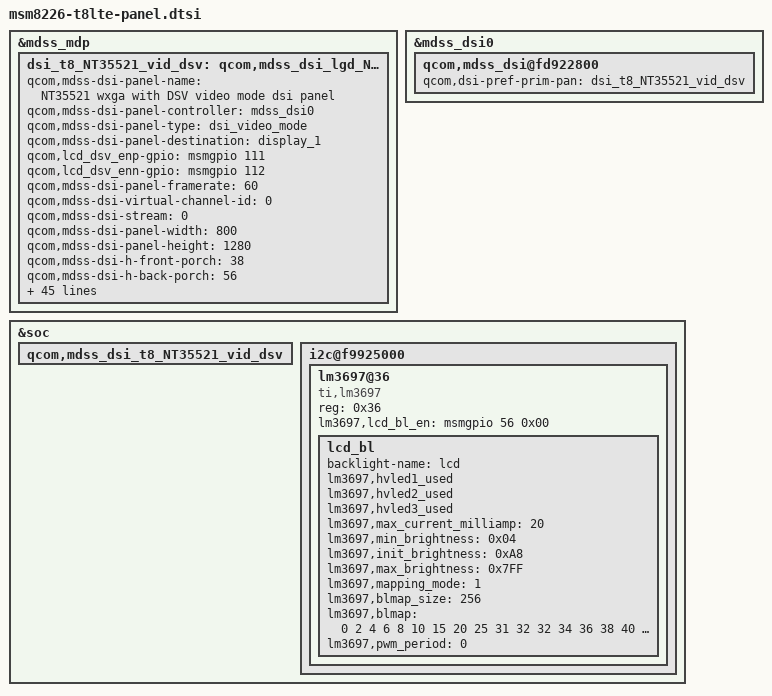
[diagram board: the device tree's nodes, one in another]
/* Copyright (c) 2013, The Linux Foundation. All rights reserved.
 *
 * This program is free software; you can redistribute it and/or modify
 * it under the terms of the GNU General Public License version 2 and
 * only version 2 as published by the Free Software Foundation.
 *
 * This program is distributed in the hope that it will be useful,
 * but WITHOUT ANY WARRANTY; without even the implied warranty of
 * MERCHANTABILITY or FITNESS FOR A PARTICULAR PURPOSE.  See the
 * GNU General Public License for more details.
 */

/*---------------------------------------------------------------------------
 * This file is autogenerated file using gcdb parser. Please do not edit it.
 * Update input XML file to add a new entry or update variable in this file
 * VERSION = "1.0"
 *---------------------------------------------------------------------------*/
&mdss_mdp {
	dsi_t8_NT35521_vid_dsv: qcom,mdss_dsi_lgd_NT35521_t8_wxga_video {
		qcom,mdss-dsi-panel-name = "NT35521 wxga with DSV video mode dsi panel";
		qcom,mdss-dsi-panel-controller = <&mdss_dsi0>;
		qcom,mdss-dsi-panel-type = "dsi_video_mode";
		qcom,mdss-dsi-panel-destination = "display_1";
		qcom,lcd_dsv_enp-gpio = <&msmgpio 111 0>;
		qcom,lcd_dsv_enn-gpio = <&msmgpio 112 0>;
		qcom,mdss-dsi-panel-framerate = <60>;
		qcom,mdss-dsi-virtual-channel-id = <0>;
		qcom,mdss-dsi-stream = <0>;
		qcom,mdss-dsi-panel-width = <800>;
		qcom,mdss-dsi-panel-height = <1280>;
		qcom,mdss-dsi-h-front-porch = <38>;
		qcom,mdss-dsi-h-back-porch = <56>;
		qcom,mdss-dsi-h-pulse-width = <4>;
		qcom,mdss-dsi-h-sync-skew = <0>;
		qcom,mdss-dsi-v-front-porch = <24>;
		qcom,mdss-dsi-v-back-porch = <32>;
		qcom,mdss-dsi-v-pulse-width = <4>;
		qcom,mdss-dsi-h-left-border = <0>;
		qcom,mdss-dsi-h-right-border = <0>;
		qcom,mdss-dsi-v-top-border = <0>;
		qcom,mdss-dsi-v-bottom-border = <0>;
		qcom,mdss-pan-physical-width-dimension = < 94 >;
		qcom,mdss-pan-physical-height-dimension = < 150 >;
		qcom,mdss-dsi-bpp = <24>;
		qcom,mdss-dsi-color-order = "rgb_swap_rgb";
		qcom,mdss-dsi-underflow-color = <0x00>;
		qcom,mdss-dsi-border-color = <0>;
		qcom,mdss-dsi-lp11-init =<1>;
		qcom,mdss-dsi-on-command = [
		39 01 00 00 00 00 05 FF AA 55 A5 80
		15 01 00 00 00 00 02 6F 02
		15 01 00 00 00 00 02 F7 47
		15 01 00 00 00 00 02 6F 17
		15 01 00 00 00 00 02 F4 60
		39 01 00 00 00 00 06 F0 55 AA 52 08 00
		39 01 00 00 00 00 03 B1 28 01
		15 01 00 00 00 00 02 B5 C8
		15 01 00 00 00 00 02 B6 05
		39 01 00 00 00 00 05 B8 01 02 0C 02
		39 01 00 00 00 00 03 BB 33 33
		39 01 00 00 00 00 03 BC 05 05
		39 01 00 00 00 00 06 BD 02 67 20 20 00
		15 01 00 00 00 00 02 D0 00
		39 01 00 00 00 00 03 D9 00 01
		15 01 00 00 00 00 02 C8 83
		39 01 00 00 00 00 11 CC 40 36 87 00 00 00 00 00 00 00 00 00 40 08 A5 05
		39 01 00 00 00 00 11 D1 00 06 0A 0E 12 16 22 28 22 20 16 14 12 0E 08 00
		39 01 00 00 00 00 0D D7 26 28 25 23 23 00 00 00 00 00 00 00
		39 01 00 00 00 00 0E D8 00 00 00 00 00 00 00 00 00 00 23 25 00
		39 01 00 00 00 00 06 F0 55 AA 52 08 01
		39 01 00 00 00 00 03 B3 19 19
		39 01 00 00 00 00 03 B4 1E 1E
		39 01 00 00 00 00 03 B9 24 24
		39 01 00 00 00 00 03 BA 36 36
		39 01 00 00 00 00 03 BC 40 10
		39 01 00 00 00 00 03 BD 40 10
		15 01 00 00 00 00 02 C1 01
		15 01 00 00 00 00 02 CA 80
		39 01 00 00 00 00 03 CB 90 F4
		39 01 00 00 00 00 04 CD 15 03 03
		39 01 00 00 00 00 04 CF 00 50 50
		39 01 00 00 00 00 03 D0 50 50
		39 01 00 00 00 00 03 D1 50 50
		15 01 00 00 00 00 02 D2 39
		15 01 00 00 00 00 02 D3 39
		39 01 00 00 00 00 06 F0 55 AA 52 08 02
		15 01 00 00 00 00 02 EE 02
		39 01 00 00 00 00 11 B0 00 44 00 55 00 6A 00 88 00 97 00 BB 00 D2 00 FE
		39 01 00 00 00 00 11 B1 01 23 01 58 01 8A 01 D2 02 11 02 13 02 49 02 87
		39 01 00 00 00 00 11 B2 02 AF 02 E5 03 0B 03 4E 03 6C 03 8E 03 A5 03 C0
		39 01 00 00 00 00 05 B3 03 E8 03 FF
		39 01 00 00 00 00 11 BC 00 0A 00 1C 00 32 00 52 00 62 00 88 00 A1 00 CE
		39 01 00 00 00 00 11 BD 00 F4 01 2F 01 63 01 B0 01 F3 01 F5 02 2E 02 70
		39 01 00 00 00 00 11 BE 02 9A 02 D3 02 FC 03 42 03 63 03 86 03 9E 03 BB
		39 01 00 00 00 00 05 BF 03 E6 03 FF
		39 01 00 00 00 00 06 F0 55 AA 52 08 03
		39 01 00 00 00 00 03 B0 22 00
		39 01 00 00 00 00 03 B1 22 00
		39 01 00 00 00 00 06 B2 05 00 B0 00 00
		39 01 00 00 00 00 06 B3 05 00 B0 00 00
		39 01 00 00 00 00 06 B4 05 00 B0 00 00
		39 01 00 00 00 00 06 B5 05 00 B0 00 00
		39 01 00 00 00 00 06 BA 53 00 B0 00 00
		39 01 00 00 00 00 06 BB 53 00 B0 00 00
		39 01 00 00 00 00 06 BC 53 00 B0 00 00
		39 01 00 00 00 00 06 BD 53 00 B0 00 00
		39 01 00 00 00 00 05 C0 00 60 00 00
		39 01 00 00 00 00 05 C1 00 00 60 00
		39 01 00 00 00 00 05 C2 00 00 34 00
		39 01 00 00 00 00 05 C3 00 00 34 00
		15 01 00 00 00 00 02 C4 60
		15 01 00 00 00 00 02 C5 C0
		15 01 00 00 00 00 02 C6 00
		15 01 00 00 00 00 02 C7 00
		39 01 00 00 00 00 06 F0 55 AA 52 08 05
		39 01 00 00 00 00 03 B0 17 06
		39 01 00 00 00 00 03 B1 17 06
		39 01 00 00 00 00 03 B2 17 06
		39 01 00 00 00 00 03 B3 17 06
		39 01 00 00 00 00 03 B4 17 06
		39 01 00 00 00 00 03 B5 17 06
		39 01 00 00 00 00 03 B6 17 06
		39 01 00 00 00 00 03 B7 17 06
		15 01 00 00 00 00 02 B8 00
		39 01 00 00 00 00 03 B9 00 03
		39 01 00 00 00 00 03 BA 00 00
		39 01 00 00 00 00 03 BB 02 03
		39 01 00 00 00 00 03 BC 02 03
		39 01 00 00 00 00 06 BD 03 03 00 03 03
		15 01 00 00 00 00 02 C0 0B
		15 01 00 00 00 00 02 C1 09
		15 01 00 00 00 00 02 C2 A6
		15 01 00 00 00 00 02 C3 05
		15 01 00 00 00 00 02 C4 00
		15 01 00 00 00 00 02 C5 02
		15 01 00 00 00 00 02 C6 22
		15 01 00 00 00 00 02 C7 03
		39 01 00 00 00 00 03 C8 07 20
		39 01 00 00 00 00 03 C9 03 20
		39 01 00 00 00 00 03 CA 01 60
		39 01 00 00 00 00 03 CB 01 60
		39 01 00 00 00 00 04 CC 00 00 78
		39 01 00 00 00 00 04 CD 00 00 78
		39 01 00 00 00 00 04 CE 00 00 02
		39 01 00 00 00 00 04 CF 00 00 02
		39 01 00 00 00 00 06 D1 00 05 01 07 10
		39 01 00 00 00 00 06 D2 10 05 05 03 10
		39 01 00 00 00 00 06 D3 20 00 43 07 10
		39 01 00 00 00 00 06 D4 30 00 43 07 10
		39 01 00 00 00 00 08 D0 00 00 00 00 00 00 00
		39 01 00 00 00 00 0C D5 00 00 00 00 00 00 00 00 00 00 00
		39 01 00 00 00 00 0C D6 00 00 00 00 00 00 00 00 00 00 00
		39 01 00 00 00 00 0C D7 00 00 00 00 00 00 00 00 00 00 00
		39 01 00 00 00 00 06 D8 00 00 00 00 00
		15 01 00 00 00 00 02 E5 06
		15 01 00 00 00 00 02 E6 06
		15 01 00 00 00 00 02 E7 00
		15 01 00 00 00 00 02 E8 06
		15 01 00 00 00 00 02 E9 06
		15 01 00 00 00 00 02 EA 06
		15 01 00 00 00 00 02 EB 00
		15 01 00 00 00 00 02 EC 00
		15 01 00 00 00 00 02 ED 30
		39 01 00 00 00 00 06 F0 55 AA 52 08 06
		39 01 00 00 00 00 03 B0 34 34
		39 01 00 00 00 00 03 B1 34 34
		39 01 00 00 00 00 03 B2 2D 2E
		39 01 00 00 00 00 03 B3 34 34
		39 01 00 00 00 00 03 B4 29 2A
		39 01 00 00 00 00 03 B5 13 11
		39 01 00 00 00 00 03 B6 19 17
		39 01 00 00 00 00 03 B7 01 03
		39 01 00 00 00 00 03 B8 34 31
		39 01 00 00 00 00 03 B9 31 31
		39 01 00 00 00 00 03 BA 31 31
		39 01 00 00 00 00 03 BB 31 34
		39 01 00 00 00 00 03 BC 02 00
		39 01 00 00 00 00 03 BD 16 18
		39 01 00 00 00 00 03 BE 10 12
		39 01 00 00 00 00 03 BF 2A 29
		39 01 00 00 00 00 03 C0 34 34
		39 01 00 00 00 00 03 C1 2E 2D
		39 01 00 00 00 00 03 C2 34 34
		39 01 00 00 00 00 03 C3 34 34
		39 01 00 00 00 00 06 D8 00 00 00 00 00
		39 01 00 00 00 00 06 D9 00 00 00 00 00
		39 01 00 00 00 00 05 FF AA 55 A5 00
		39 01 00 00 00 00 06 F0 55 AA 52 00 00
		05 01 00 00 78 00 02 11 00
		15 01 00 00 00 00 02 51 FF
		15 01 00 00 00 00 02 53 24
		15 01 00 00 00 00 02 55 80
		05 01 00 00 00 00 02 29 00];
		qcom,mdss-dsi-off-command = [
		05 01 00 00 32 00 02 28 00
		05 01 00 00 78 00 02 10 00
		];
		qcom,mdss-dsi-on-command-state = "dsi_lp_mode";
		qcom,mdss-dsi-off-command-state = "dsi_hs_mode";
		qcom,mdss-dsi-h-sync-pulse = <0>;
		qcom,mdss-dsi-traffic-mode = "non_burst_sync_event";
		qcom,mdss-dsi-lane-map = "lane_map_0123";
		qcom,mdss-dsi-bllp-eof-power-mode;
		qcom,mdss-dsi-bllp-power-mode;
		qcom,mdss-dsi-lane-0-state;
		qcom,mdss-dsi-lane-1-state;
		qcom,mdss-dsi-lane-2-state;
		qcom,mdss-dsi-lane-3-state;
		qcom,mdss-dsi-panel-timings = [7A 1A 12 00 40 4C 12 20 14 03 04 00];
		qcom,mdss-dsi-t-clk-post = <0x04>;
		qcom,mdss-dsi-t-clk-pre = <0x1A>;
		qcom,mdss-dsi-bl-min-level = <1>;
		qcom,mdss-dsi-bl-max-level = <255>;
		qcom,mdss-dsi-dma-trigger = "trigger_sw";
		qcom,mdss-dsi-mdp-trigger = "none";
		qcom,mdss-dsi-bl-pmic-control-type = "bl_ctrl_wled";
		qcom,mdss-dsi-reset-sequence = <1 1>, <0 1>, <1 150>;
	};
};

&mdss_dsi0 {
	qcom,mdss_dsi@fd922800 {
		qcom,dsi-pref-prim-pan = <&dsi_t8_NT35521_vid_dsv>;
	};
};

&dsi_t8_NT35521_vid_dsv {
	qcom,cont-splash-enabled;
	qcom,platform-enable-gpio = <0>;
	status = "ok";
};

&soc {
	qcom,mdss_dsi_t8_NT35521_vid_dsv {
		status = "ok";
	};

    i2c@f9925000 { /* BLSP1 QUP3 */
	lm3697@36 {
		compatible = "ti,lm3697";
		status = "ok";
		reg = <0x36>;
		lm3697,lcd_bl_en = <&msmgpio 56 0x00>;
		lcd_bl {
			backlight-name = "lcd";
			lm3697,hvled1_used;
			lm3697,hvled2_used;
			lm3697,hvled3_used;
			lm3697,max_current_milliamp = <20>;
			lm3697,min_brightness = <0x04>;
			lm3697,init_brightness = <0xA8>;
			lm3697,max_brightness = <0x7FF>;
			/* mapping_mode, 0: exp, 1: linear */
			lm3697,mapping_mode = <1>;
			lm3697,blmap_size = <256>;
			lm3697,blmap = <
				0 2 4 6 8 10 15 20 25 31                              /* 0 ~ 9  */
				32 32 34 36 38 40 42 44 46 48                         /* 10 ~ 19 */
				50 52 54 54 56 56 58 58 60 60                         /* 20 ~ 29 */
				62 62 64 64 66 66 68 68 70 70                         /* 30 ~ 39 */
				72 74 74 76 78 78 80 82 82 84                         /* 40 ~ 49 */
				86 86 88 88 90 90 92 92 94 96                         /* 50 ~ 59 */
				96 96 100 104 108 112 116 120 124 128                 /* 60 ~ 69 */
				132 136 140 144 148 152 156 160 164 168               /* 70 ~ 79 */
				172 176 180 184 188 192 196 200 204 208               /* 80 ~ 89 */
				212 216 220 224 228 232 236 240 244 248               /* 90 ~ 99 */
				252 256 260 264 268 272 273 277 280 287               /* 100 ~ 109 */
				295 303 311 318 326 334 342 350 358 366               /* 110 ~ 119 */
				374 382 390 398 405 412 419 426 433 440               /* 120 ~ 129 */
				447 454 461 468 475 482 489 496 503 510               /* 130 ~ 139 */
				517 524 531 538 545 552 559 565 572 579               /* 140 ~ 149 */
				586 593 600 608 616 624 632 640 648 659               /* 150 ~ 159 */
				670 681 692 703 714 725 736 747 758 769               /* 160 ~ 169 */
				780 792 804 816 828 840 852 864 876 888               /* 170 ~ 179 */
				900 912 924 936 948 960 972 984 996 1008              /* 180 ~ 189 */
				1020 1028 1040 1052 1064 1076 1088 1100 1111 1122     /* 190 ~ 199 */
				1133 1144 1155 1166 1177 1188 1199 1208 1225 1242     /* 200 ~ 209 */
				1259 1276 1293 1310 1328 1346 1364 1382 1400 1417     /* 210 ~ 219 */
				1434 1451 1468 1485 1502 1519 1536 1553 1570 1587     /* 220 ~ 229 */
				1605 1623 1640 1658 1676 1694 1712 1730 1748 1766     /* 230 ~ 239 */
				1784 1800 1818 1836 1854 1872 1880 1898 1915 1933     /* 240 ~ 249 */
				1950 1973 1992 2010 2028 2047>;                       /* 250 ~ 255 */
			lm3697,pwm_period = <0>;
		};
        };
    };
};
